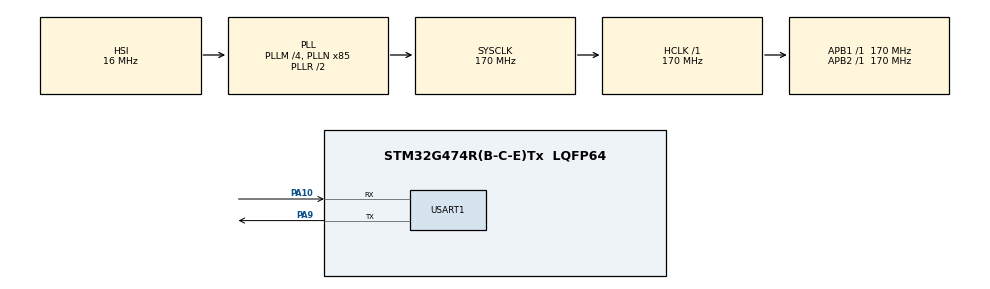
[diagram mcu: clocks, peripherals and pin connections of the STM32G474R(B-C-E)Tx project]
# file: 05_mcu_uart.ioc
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Mcu.Family=STM32G4
Mcu.Name=STM32G474R(B-C-E)Tx
Mcu.Package=LQFP64
NVIC.PriorityGroup=NVIC_PRIORITYGROUP_4
PA10.Mode=Asynchronous
PA10.Signal=USART1_RX
PA13.Mode=Serial_Wire
PA13.Signal=SYS_JTMS-SWDIO
PA14.Mode=Serial_Wire
PA14.Signal=SYS_JTCK-SWCLK
PA9.Mode=Asynchronous
PA9.Signal=USART1_TX
ProjectManager.HeapSize=0x200
ProjectManager.StackSize=0x400
ProjectManager.TargetToolchain=CMake
RCC.ADC12Freq_Value=170000000
RCC.ADC345Freq_Value=170000000
RCC.AHBFreq_Value=170000000
RCC.APB1Freq_Value=170000000
RCC.APB1TimFreq_Value=170000000
RCC.APB2Freq_Value=170000000
RCC.APB2TimFreq_Value=170000000
RCC.CortexFreq_Value=170000000
RCC.EXTERNAL_CLOCK_VALUE=12288000
RCC.HCLKFreq_Value=170000000
RCC.HSE_VALUE=8000000
RCC.HSI48_VALUE=48000000
RCC.HSI_VALUE=16000000
RCC.LSE_VALUE=32768
RCC.PLLM=RCC_PLLM_DIV4
RCC.PLLN=85
RCC.SYSCLKFreq_VALUE=170000000
RCC.SYSCLKSource=RCC_SYSCLKSOURCE_PLLCLK
RCC.USBFreq_Value=170000000
RCC.VCOOutputFreq_Value=340000000
USART1.VirtualMode-Asynchronous=VM_ASYNC
VP_SYS_VS_DBSignals.Mode=DisableDeadBatterySignals
board=custom

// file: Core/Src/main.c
/* USER CODE BEGIN Header */
/**
  ******************************************************************************
  * @file           : main.c
  * @brief          : Main program body
  ******************************************************************************
  * @attention
  *
  * Copyright (c) 2026 STMicroelectronics.
  * All rights reserved.
  *
  * This software is licensed under terms that can be found in the LICENSE file
  * in the root directory of this software component.
  * If no LICENSE file comes with this software, it is provided AS-IS.
  *
  ******************************************************************************
  */
/* USER CODE END Header */
#include "main.h"
#include "usart.h"
#include "gpio.h"

void SystemClock_Config(void);

int main(void)
{

  /* MCU Configuration--------------------------------------------------------*/

  /* Reset of all peripherals, Initializes the Flash interface and the Systick. */
  HAL_Init();

  /* Configure the system clock */
  SystemClock_Config();

  /* Initialize all configured peripherals */
  MX_GPIO_Init();
  MX_USART1_UART_Init();
  /* USER CODE BEGIN 2 */
  uint8_t rx_data;
  /* USER CODE END 2 */

  /* Infinite loop */
  while (1)
  {

    /* USER CODE BEGIN 3 */
    // HAL_UART_Transmit(&huart1, "hello\r\n", 7, 0xFFFF);
    // rx_data = HAL_UART_Receive(&huart1, &rx_data, 1, 0xFFFF);
    // HAL_Delay(1000);
    // HAL_UART_Transmit(&huart1, &rx_data, 1, 0xFFFF);
#if 0
    // 1. 接收数据：传入 rx_data 的地址 &rx_data
    // 注意：用一个变量接收返回值来判断是否接收成功（可选）
    HAL_StatusTypeDef status = HAL_UART_Receive(&huart1, &rx_data, 1, HAL_MAX_DELAY);
    // 3. 延时（根据你的需求保留，但通常回显不加延时以防丢失后续数据）
    HAL_Delay(3000);

    HAL_UART_Transmit(&huart1, "hello\r\n", 7, 0xFFFF);//等待3秒，接收到数据之后才会发送回显hello

    // 2. 如果接收成功，则将数据发送回去（回显）
    if (status == HAL_OK)
    {
        HAL_UART_Transmit(&huart1, &rx_data, 1, HAL_MAX_DELAY);
    }
#endif
#if 0
    // 1. 接收数据：传入 rx_data 的地址 &rx_data
    // 注意：用一个变量接收返回值来判断是否接收成功（可选）
    HAL_StatusTypeDef status = HAL_UART_Receive(&huart1, &rx_data, 3, HAL_MAX_DELAY);//等待接收到数据之后才会发送回显hello
    // 3. 延时（根据你的需求保留，但通常回显不加延时以防丢失后续数据）
    HAL_Delay(1000);

    HAL_UART_Transmit(&huart1, "hello\r\n", 7, 10);

    // 2. 如果接收成功，则将数据发送回去（回显）
    if (status == HAL_OK)
    {
        HAL_UART_Transmit(&huart1, &rx_data, 1, 10);
    }
#endif
    // uint8_t rx_byte;
    // 等待 RK3576 发送一个字节
    if (HAL_UART_Receive(&huart1,
                         &rx_data,
                         1,
                         HAL_MAX_DELAY) == HAL_OK)
    {
        // 收到什么，就原样发送回去
        HAL_UART_Transmit(&huart1,
                          &rx_data,
                          1,
                          1000);
    }

  }
  /* USER CODE END 3 */
}

void SystemClock_Config(void)
{
  RCC_OscInitTypeDef RCC_OscInitStruct = {0};
  RCC_ClkInitTypeDef RCC_ClkInitStruct = {0};

  /** Configure the main internal regulator output voltage
  */
  HAL_PWREx_ControlVoltageScaling(PWR_REGULATOR_VOLTAGE_SCALE1_BOOST);

  /** Initializes the RCC Oscillators according to the specified parameters
  * in the RCC_OscInitTypeDef structure.
  */
  RCC_OscInitStruct.OscillatorType = RCC_OSCILLATORTYPE_HSI;
  RCC_OscInitStruct.HSIState = RCC_HSI_ON;
  RCC_OscInitStruct.HSICalibrationValue = RCC_HSICALIBRATION_DEFAULT;
  RCC_OscInitStruct.PLL.PLLState = RCC_PLL_ON;
  RCC_OscInitStruct.PLL.PLLSource = RCC_PLLSOURCE_HSI;
  RCC_OscInitStruct.PLL.PLLM = RCC_PLLM_DIV4;
  RCC_OscInitStruct.PLL.PLLN = 85;
  RCC_OscInitStruct.PLL.PLLP = RCC_PLLP_DIV2;
  RCC_OscInitStruct.PLL.PLLQ = RCC_PLLQ_DIV2;
  RCC_OscInitStruct.PLL.PLLR = RCC_PLLR_DIV2;
  if (HAL_RCC_OscConfig(&RCC_OscInitStruct) != HAL_OK)
  {
    Error_Handler();
  }

  /** Initializes the CPU, AHB and APB buses clocks
  */
  RCC_ClkInitStruct.ClockType = RCC_CLOCKTYPE_HCLK|RCC_CLOCKTYPE_SYSCLK
                              |RCC_CLOCKTYPE_PCLK1|RCC_CLOCKTYPE_PCLK2;
  RCC_ClkInitStruct.SYSCLKSource = RCC_SYSCLKSOURCE_PLLCLK;
  RCC_ClkInitStruct.AHBCLKDivider = RCC_SYSCLK_DIV1;
  RCC_ClkInitStruct.APB1CLKDivider = RCC_HCLK_DIV1;
  RCC_ClkInitStruct.APB2CLKDivider = RCC_HCLK_DIV1;

  if (HAL_RCC_ClockConfig(&RCC_ClkInitStruct, FLASH_LATENCY_4) != HAL_OK)
  {
    Error_Handler();
  }
}

void Error_Handler(void)
{
  __disable_irq();
  while (1)
  {
  }
}
